# nrf9230_engb_application register map
Vendor: Nordic Semiconductor; Series: nRF92; File version: 1
CPU: CM33 r0p4, little endian, MPU, FPU, 3 interrupt priority bits, 480 interrupts, 4 SAU regions
Registers are 32-bit, read-write, reset 0x0 unless marked. A register's access mark holds for its fields unless they carry their own. Offsets are from the block's base; [hi:lo] are bit positions; 'fields as' and 'values as' point back to an identical list.

## GLOBAL_DMU120_NS — DMU 0
Base 0x2FBEF800
Same registers: GLOBAL_DMU121_NS 0x2FBF7800
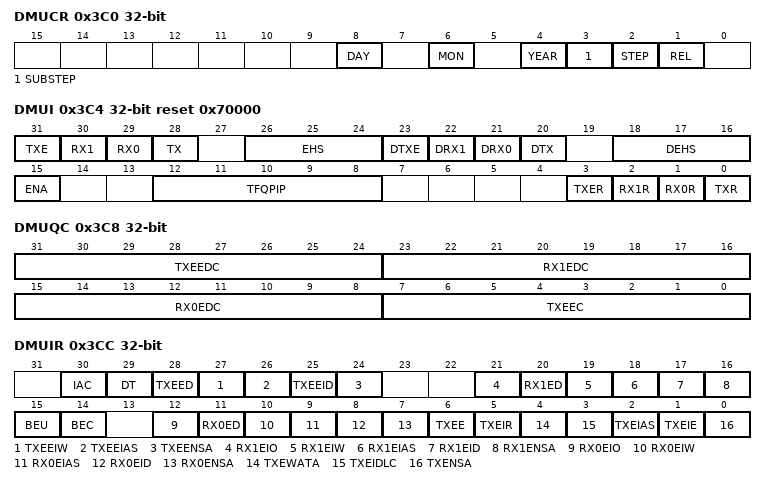
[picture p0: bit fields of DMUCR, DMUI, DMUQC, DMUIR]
0x3C0 DMUCR ro — DMU Core Release
  [8] DAY — Time Stamp Day
  [6] MON — Time Stamp Month
  [4] YEAR — Time Stamp Year
  [3] SUBSTEP — Sub-step of Core Release
  [2] STEP — Step of Core Release
  [1] REL — Core Release
0x3C4 DMUI reset 0x70000 — DMU Internals
  [31] TXE — Actual DMU Element Service
    0=NotServed (DMU Virtual Buffer is currently not served); 1=Served (DMU Virtual Buffer is currently served)
  [30] RX1 — Actual DMU Element Service
    values as TXE
  [29] RX0 — Actual DMU Element Service
    values as TXE
  [28] TX — Actual DMU Element Service
    values as TXE
  [26:24] EHS — Element Handler State
    0=wait4cce (wait for bit MCAN:CCCR.CCE getting zero); 1=wait4sa (wait for Start Address); 2=wait4ta (wait for Trigger Address); 3=transfer (wait for transfer of Element word); 4=ack2mcan (acknowledge to MCAN); 5=recovery (exception recovery)
  [23] DTXE — Detect DMU Element Service
    0=Disabled (Queueing of DMU Element does not activate interrupt flag); 1=Enabled (Queueing of DMU Element will activate interrupt flag when DMUI.EHS = DMUI.DEHS)
  [22] DRX1 — Detect DMU Element Service
    values as DTXE
  [21] DRX0 — Detect DMU Element Service
    values as DTXE
  [20] DTX — Detect DMU Element Service
    values as DTXE
  [18:16] DEHS — Detect Element Handler State
  [15] ENA — DMU is enabled
    0=Disabled (DMU is disabled); 1=Enabled (DMU is enabled and can process DMA data)
  [12:8] TFQPIP — TX FIFO/Queue Put Index Previous
  [3] TXER — TX Event Service Request line of DMU
    0=NotRequested (No TX Event DMA service requested); 1=Requested (TX Event DMA Service requested)
  [2] RX1R — RX1 Service Request line of DMU
    0=NotRequested (No RX1 DMA service requested); 1=Requested (RX1 DMA Service requested)
  [1] RX0R — RX0 Service Request line of DMU
    0=NotRequested (No RX0 DMA service requested); 1=Requested (RX0 DMA Service requested)
  [0] TXR — TX Service Request line of DMU
    0=NotRequested (No TX DMA service requested); 1=Requested (TX DMA Service requested)
0x3C8 DMUQC — DMU Queueing Counter
  [31:24] TXEEDC — TX Event Element Dequeueing Counter
  [23:16] RX1EDC — RX1 Element Dequeueing Counter
  [15:8] RX0EDC — RX0 Element Dequeueing Counter
  [7:0] TXEEC — TX Element Enqueueing Counter
0x3CC DMUIR — DMU Interrupt Register
  [30] IAC — Illegal Access while in Configuration mode
    1=Clear (Write '1' to clear interrupt flag); 0=NotGenerated (No Illegal Access while CCE mode); 1=Generated (Illegal Access while CCE mode)
  [29] DT — Debug Trigger
    1=Clear (Write '1' to clear interrupt flag); 0=NotGenerated (Debug point not reached); 1=Generated (Debug point reached)
  [28] TXEED — TX Event Element Dequeued
    1=Clear (Write '1' to clear interrupt flag); 0=NotGenerated (No TX Event Element dequeued); 1=Generated (TX Event Element successfully dequeued)
  [27] TXEEIW — TX Event Element Illegal Write
    1=Clear (Write '1' to clear interrupt flag); 0=NotGenerated (No write access detected); 1=Generated (Illegal write access to DMU TX Event Element detected, exception recovery started.)
  [26] TXEEIAS — TX Event Element Illegal Access Sequence
    1=Clear (Write '1' to clear interrupt flag); 0=NotGenerated (No illegal addressing sequence detected); 1=Generated (Accesses are not strictly linear to ascending and consecutive addresses, exception recovery started.)
  [25] TXEEID — TX Event Element Illegal Dequeueing
    1=Clear (Write '1' to clear interrupt flag); 0=NotGenerated (No illegal dequeueing); 1=Generated (Start of dequeueing without request detected, exception recovery started.)
  [24] TXEENSA — TX Event Element Not Start Address
    1=Clear (Write '1' to clear interrupt flag); 0=NotGenerated (No illegal read access); 1=Generated (Read from TX Event Element begins without using start address, exception recovery started.)
  [21] RX1EIO — RX1 Element Illegal Overwrite by timestamp
    1=Clear (Write '1' to clear interrupt flag); 0=NotGenerated (No illegal overwrite detected); 1=Generated (DMU has internally overwritten the last element word of a SYNC message)
  [20] RX1ED — RX0 Element Dequeued
    1=Clear (Write '1' to clear interrupt flag); 0=NotGenerated (No Rx message dequeued); 1=Generated (Rx message successfully dequeued)
  [19] RX1EIW — RX1 Element Illegal Write
    1=Clear (Write '1' to clear interrupt flag); 0=NotGenerated (No write access detected); 1=Generated (Illegal write access to DMU RX1 Element detected, exception recovery started.)
  [18] RX1EIAS — RX0 Element Illegal Access Sequence
    values as TXEEIAS
  [17] RX1EID — RX1 Element Illegal Dequeueing
    1=Clear (Write '1' to clear interrupt flag); 0=NotGenerated (No illegal dequeueing); 1=Generated (Start of dequeueing without request detected, exception recovery started,)
  [16] RX1ENSA — RX1 Element Not Start Address
    1=Clear (Write '1' to clear interrupt flag); 0=NotGenerated (No illegal read access); 1=Generated (Read from RX1 Element begins without using start address, exception recovery started.)
  [15] BEU — Bus Error Uncorrected
    1=Clear (Write '1' to clear interrupt flag); 0=NotGenerated (No read slave error detected when reading from Message RAM); 1=Generated (Read slave error detected)
  [14] BEC — Bit Error Corrected
    1=Clear (Write '1' to clear interrupt flag); 0=NotGenerated (No bit error detected when reading from Message RAM); 1=Generated (Bit error detected and corrected)
  [12] RX0EIO — RX0 Element Illegal Overwrite by timestamp
    values as RX1EIO
  [11] RX0ED — RX0 Element Dequeued
    values as RX1ED
  [10] RX0EIW — RX0 Element Illegal Write
    1=Clear (Write '1' to clear interrupt flag); 0=NotGenerated (No write access detected); 1=Generated (Illegal write access to DMU RX0 Element detected, exception recovery started.)
  [9] RX0EIAS — RX0 Element Illegal Access Sequence
    values as TXEEIAS
  [8] RX0EID — RX0 Element Illegal Dequeueing
    values as RX1EID
  [7] RX0ENSA — RX0 Element Not Start Address
    1=Clear (Write '1' to clear interrupt flag); 0=NotGenerated (No illegal read access); 1=Generated (Read from RX0 Element begins without using start address, exception recovery started.)
  [6] TXEE — A successful enqueueing of a Tx message with the DMU TX Element section sets this flag.
    1=Clear (Write '1' to clear interrupt flag); 0=NotGenerated (No Tx message enqueued); 1=Generated (Tx message successfully enqueued)
  [5] TXEIR — TX Element Illegal Read
    1=Clear (Write '1' to clear interrupt flag); 0=NotGenerated (No read access); 1=Generated (Illegal read access to DMU TX Element section detected, exception recovery started.)
  [4] TXEWATA — TX Element Write After Trigger Address
    1=Clear (Write '1' to clear interrupt flag); 0=NotGenerated (No write after Trigger Address); 1=Generated (Write after Trigger address detected)
  [3] TXEIDLC — TX Element Illegal DLC
    1=Clear (Write '1' to clear interrupt flag); 0=NotGenerated (No illegal DLC detected); 1=Generated (DLC exceeds Tx Buffer element size of MCAN, exception recovery started.)
  [2] TXEIAS — TX Element Illegal Access Sequence
    values as TXEEIAS
  [1] TXEIE — TX Element Illegal Enqueueing
    1=Clear (Write '1' to clear interrupt flag); 0=NotGenerated (No illegal enqueueing); 1=Generated (Start of enqueueing without request detected, exception recovery started.)
  [0] TXENSA — TX Element Not Start Address
    1=Clear (Write '1' to clear interrupt flag); 0=NotGenerated (No illegal write access); 1=Generated (Write to TX Element begins without using start address, exception recovery started.)
0x3D0 DMUIE — DMU Interrupt Enable
  [0] TXENSAE — TX Element Not Start Address Enable
    0=Disabled (Flag does not activate the interrupt line DMU); 1=Enabled (the interrupt line DMU will be activated)
0x3D4 DMUC — DMU Configuration
  [0] TTS — Transfer Timestamp
    0=Disabled (No timestamp will be transferred via DMU Virtual Buffer); 1=Enabled (Timestamp of message will be transferred from TSU via DMU Virtual Buffer)

## Notices in the file
Copyright (c) 2010 - 2024, Nordic Semiconductor ASA
All rights reserved.
Redistribution and use in source and binary forms, with or without modification,
are permitted provided that the following conditions are met:
1. Redistributions of source code must retain the above copyright notice, this
list of conditions and the following disclaimer.
2. Redistributions in binary form, except as embedded into a Nordic
Semiconductor ASA integrated circuit in a product or a software update for
such product, must reproduce the above copyright notice, this list of
conditions and the following disclaimer in the documentation and/or other
materials provided with the distribution.
3. Neither the name of Nordic Semiconductor ASA nor the names of its
contributors may be used to endorse or promote products derived from this
software without specific prior written permission.
4. This software, with or without modification, must only be used with a
Nordic Semiconductor ASA integrated circuit.
5. Any software provided in binary form under this license must not be reverse
engineered, decompiled, modified and/or disassembled.
THIS SOFTWARE IS PROVIDED BY NORDIC SEMICONDUCTOR ASA "AS IS" AND ANY EXPRESS
OR IMPLIED WARRANTIES, INCLUDING, BUT NOT LIMITED TO, THE IMPLIED WARRANTIES
OF MERCHANTABILITY, NONINFRINGEMENT, AND FITNESS FOR A PARTICULAR PURPOSE ARE
DISCLAIMED. IN NO EVENT SHALL NORDIC SEMICONDUCTOR ASA OR CONTRIBUTORS BE
LIABLE FOR ANY DIRECT, INDIRECT, INCIDENTAL, SPECIAL, EXEMPLARY, OR
CONSEQUENTIAL DAMAGES (INCLUDING, BUT NOT LIMITED TO, PROCUREMENT OF SUBSTITUTE
GOODS OR SERVICES; LOSS OF USE, DATA, OR PROFITS; OR BUSINESS INTERRUPTION)
HOWEVER CAUSED AND ON ANY THEORY OF LIABILITY, WHETHER IN CONTRACT, STRICT
LIABILITY, OR TORT (INCLUDING NEGLIGENCE OR OTHERWISE) ARISING IN ANY WAY OUT
OF THE USE OF THIS SOFTWARE, EVEN IF ADVISED OF THE POSSIBILITY OF SUCH DAMAGE.
